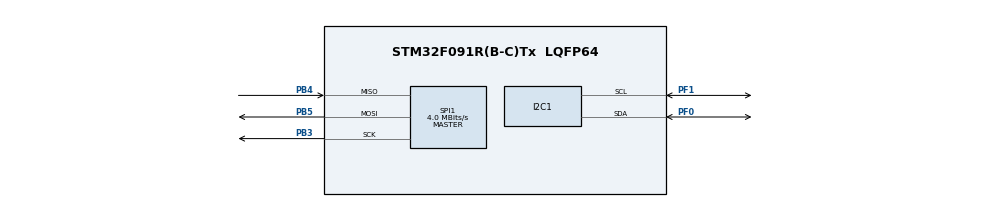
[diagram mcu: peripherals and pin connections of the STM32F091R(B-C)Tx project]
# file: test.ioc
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Mcu.Family=STM32F0
Mcu.Name=STM32F091R(B-C)Tx
Mcu.Package=LQFP64
PA13.Mode=Serial_Wire
PA13.Signal=SYS_SWDIO
PA14.Mode=Serial_Wire
PA14.Signal=SYS_SWCLK
PB3.Mode=Full_Duplex_Master
PB3.Signal=SPI1_SCK
PB4.Mode=Full_Duplex_Master
PB4.Signal=SPI1_MISO
PB5.Mode=Full_Duplex_Master
PB5.Signal=SPI1_MOSI
PF0-OSC_IN.Mode=I2C
PF0-OSC_IN.Signal=I2C1_SDA
PF1-OSC_OUT.Mode=I2C
PF1-OSC_OUT.Signal=I2C1_SCL
ProjectManager.HeapSize=0x200
ProjectManager.StackSize=0x400
ProjectManager.TargetToolchain=STM32CubeIDE
SPI1.CalculateBaudRate=4.0 MBits/s
SPI1.Direction=SPI_DIRECTION_2LINES
SPI1.Mode=SPI_MODE_MASTER
SPI1.VirtualType=VM_MASTER
VP_TIM7_VS_ClockSourceINT.Mode=Enable_Timer
board=custom

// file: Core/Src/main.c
/* USER CODE BEGIN Header */
/**
  ******************************************************************************
  * @file           : main.c
  * @brief          : Main program body
  ******************************************************************************
  * @attention
  *
  * Copyright (c) 2022 STMicroelectronics.
  * All rights reserved.
  *
  * This software is licensed under terms that can be found in the LICENSE file
  * in the root directory of this software component.
  * If no LICENSE file comes with this software, it is provided AS-IS.
  *
  ******************************************************************************
  */
/* USER CODE END Header */
#include "main.h"

I2C_HandleTypeDef hi2c1;

SPI_HandleTypeDef hspi1;

TIM_HandleTypeDef htim7;

/* USER CODE BEGIN PV */
/* Buffer used for transmission */
uint8_t aTxBuffer[] = "****SPI - Two Boards communication based on Interrupt **** SPI Message ******** SPI Message ******** SPI Message ****";

/* Buffer used for reception */
uint8_t aRxBuffer[BUFFERSIZE];
/* USER CODE END PV */

void SystemClock_Config(void);
static void MX_GPIO_Init(void);
static void MX_I2C1_Init(void);
static void MX_SPI1_Init(void);
static void MX_TIM7_Init(void);

int main(void)
{

  /* MCU Configuration--------------------------------------------------------*/

  /* Reset of all peripherals, Initializes the Flash interface and the Systick. */
  HAL_Init();

  /* Configure the system clock */
  SystemClock_Config();

  /* Initialize all configured peripherals */
  MX_GPIO_Init();
  MX_I2C1_Init();
  MX_SPI1_Init();
  MX_TIM7_Init();

  /* Infinite loop */
  while (1)
  {
	  HAL_SPI_Transmit(&hspi1, (uint8_t*)aTxBuffer, BUFFERSIZE, 100);
  }
}

void SystemClock_Config(void)
{
  RCC_OscInitTypeDef RCC_OscInitStruct = {0};
  RCC_ClkInitTypeDef RCC_ClkInitStruct = {0};
  RCC_PeriphCLKInitTypeDef PeriphClkInit = {0};

  /** Initializes the RCC Oscillators according to the specified parameters
  * in the RCC_OscInitTypeDef structure.
  */
  RCC_OscInitStruct.OscillatorType = RCC_OSCILLATORTYPE_HSI;
  RCC_OscInitStruct.HSIState = RCC_HSI_ON;
  RCC_OscInitStruct.HSICalibrationValue = RCC_HSICALIBRATION_DEFAULT;
  RCC_OscInitStruct.PLL.PLLState = RCC_PLL_NONE;
  if (HAL_RCC_OscConfig(&RCC_OscInitStruct) != HAL_OK)
  {
    Error_Handler();
  }

  /** Initializes the CPU, AHB and APB buses clocks
  */
  RCC_ClkInitStruct.ClockType = RCC_CLOCKTYPE_HCLK|RCC_CLOCKTYPE_SYSCLK
                              |RCC_CLOCKTYPE_PCLK1;
  RCC_ClkInitStruct.SYSCLKSource = RCC_SYSCLKSOURCE_HSI;
  RCC_ClkInitStruct.AHBCLKDivider = RCC_SYSCLK_DIV1;
  RCC_ClkInitStruct.APB1CLKDivider = RCC_HCLK_DIV1;

  if (HAL_RCC_ClockConfig(&RCC_ClkInitStruct, FLASH_LATENCY_0) != HAL_OK)
  {
    Error_Handler();
  }
  PeriphClkInit.PeriphClockSelection = RCC_PERIPHCLK_I2C1;
  PeriphClkInit.I2c1ClockSelection = RCC_I2C1CLKSOURCE_HSI;
  if (HAL_RCCEx_PeriphCLKConfig(&PeriphClkInit) != HAL_OK)
  {
    Error_Handler();
  }
}

static void MX_I2C1_Init(void)
{

  hi2c1.Instance = I2C1;
  hi2c1.Init.Timing = 0x2000090E;
  hi2c1.Init.OwnAddress1 = 0;
  hi2c1.Init.AddressingMode = I2C_ADDRESSINGMODE_7BIT;
  hi2c1.Init.DualAddressMode = I2C_DUALADDRESS_DISABLE;
  hi2c1.Init.OwnAddress2 = 0;
  hi2c1.Init.OwnAddress2Masks = I2C_OA2_NOMASK;
  hi2c1.Init.GeneralCallMode = I2C_GENERALCALL_DISABLE;
  hi2c1.Init.NoStretchMode = I2C_NOSTRETCH_DISABLE;
  if (HAL_I2C_Init(&hi2c1) != HAL_OK)
  {
    Error_Handler();
  }

  /** Configure Analogue filter
  */
  if (HAL_I2CEx_ConfigAnalogFilter(&hi2c1, I2C_ANALOGFILTER_ENABLE) != HAL_OK)
  {
    Error_Handler();
  }

  /** Configure Digital filter
  */
  if (HAL_I2CEx_ConfigDigitalFilter(&hi2c1, 0) != HAL_OK)
  {
    Error_Handler();
  }

}

static void MX_SPI1_Init(void)
{

  /* SPI1 parameter configuration*/
  hspi1.Instance = SPI1;
  hspi1.Init.Mode = SPI_MODE_MASTER;
  hspi1.Init.Direction = SPI_DIRECTION_2LINES;
  hspi1.Init.DataSize = SPI_DATASIZE_4BIT;
  hspi1.Init.CLKPolarity = SPI_POLARITY_LOW;
  hspi1.Init.CLKPhase = SPI_PHASE_1EDGE;
  hspi1.Init.NSS = SPI_NSS_SOFT;
  hspi1.Init.BaudRatePrescaler = SPI_BAUDRATEPRESCALER_2;
  hspi1.Init.FirstBit = SPI_FIRSTBIT_MSB;
  hspi1.Init.TIMode = SPI_TIMODE_DISABLE;
  hspi1.Init.CRCCalculation = SPI_CRCCALCULATION_DISABLE;
  hspi1.Init.CRCPolynomial = 7;
  hspi1.Init.CRCLength = SPI_CRC_LENGTH_DATASIZE;
  hspi1.Init.NSSPMode = SPI_NSS_PULSE_ENABLE;
  if (HAL_SPI_Init(&hspi1) != HAL_OK)
  {
    Error_Handler();
  }

}

static void MX_TIM7_Init(void)
{

  TIM_MasterConfigTypeDef sMasterConfig = {0};

  htim7.Instance = TIM7;
  htim7.Init.Prescaler = 0;
  htim7.Init.CounterMode = TIM_COUNTERMODE_UP;
  htim7.Init.Period = 65535;
  htim7.Init.AutoReloadPreload = TIM_AUTORELOAD_PRELOAD_DISABLE;
  if (HAL_TIM_Base_Init(&htim7) != HAL_OK)
  {
    Error_Handler();
  }
  sMasterConfig.MasterOutputTrigger = TIM_TRGO_RESET;
  sMasterConfig.MasterSlaveMode = TIM_MASTERSLAVEMODE_DISABLE;
  if (HAL_TIMEx_MasterConfigSynchronization(&htim7, &sMasterConfig) != HAL_OK)
  {
    Error_Handler();
  }

}

static void MX_GPIO_Init(void)
{

  /* GPIO Ports Clock Enable */
  __HAL_RCC_GPIOF_CLK_ENABLE();
  __HAL_RCC_GPIOA_CLK_ENABLE();
  __HAL_RCC_GPIOB_CLK_ENABLE();

}

void Error_Handler(void)
{
  __disable_irq();
  while (1)
  {
  }
}
